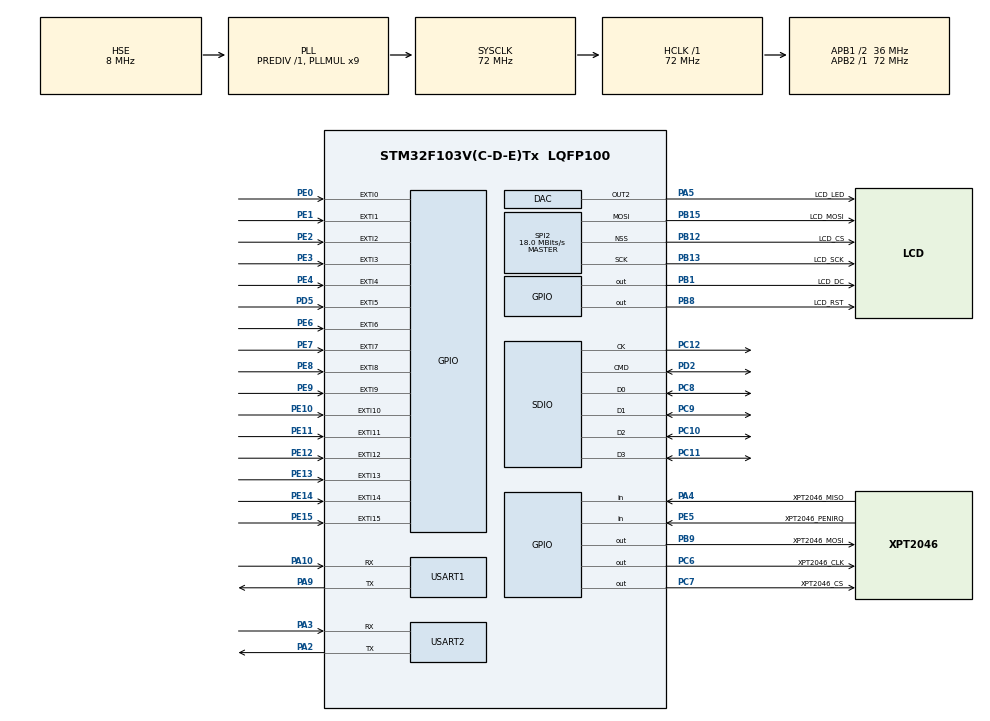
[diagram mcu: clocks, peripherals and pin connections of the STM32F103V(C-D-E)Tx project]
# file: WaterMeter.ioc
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DAC.DAC_Trigger2=DAC_TRIGGER_NONE
Dma.Request0=SPI2_TX
Dma.SPI2_TX.0.Direction=DMA_MEMORY_TO_PERIPH
Dma.SPI2_TX.0.Instance=DMA1_Channel5
Dma.SPI2_TX.0.MemDataAlignment=DMA_MDATAALIGN_BYTE
Dma.SPI2_TX.0.MemInc=DMA_MINC_ENABLE
Dma.SPI2_TX.0.Mode=DMA_NORMAL
Dma.SPI2_TX.0.PeriphDataAlignment=DMA_PDATAALIGN_BYTE
Dma.SPI2_TX.0.PeriphInc=DMA_PINC_DISABLE
Dma.SPI2_TX.0.Priority=DMA_PRIORITY_VERY_HIGH
FATFS._CODE_PAGE=437
FATFS._USE_LFN=2
FREERTOS.Tasks01=defaultTask,24,128,StartDefaultTask,Default,NULL,Dynamic,NULL,NULL;Task_Exti,8,150,TaskFunc_Exti,As external,NULL,Static,Task_ExtiBuffer,Task_ExtiControlBlock;Task_Screen,40,550,TaskFunc_Screen,As external,NULL,Static,Task_ScreenBuffer,Task_ScreenControlBlock;Task_Air724Rx,8,128,TaskFunc_Air724Rx,As external,NULL,Static,Task_Air724RxBuffer,Task_Air724RxControlBlock;Task_Air724Tx,8,128,TaskFunc_Air724Tx,As external,NULL,Static,Task_Air724TxBuffer,Task_Air724TxControlBlock
FREERTOS.configMAX_TASK_NAME_LEN=32
FREERTOS.configRECORD_STACK_HIGH_ADDRESS=1
FREERTOS.configTOTAL_HEAP_SIZE=2048
FREERTOS.configUSE_NEWLIB_REENTRANT=1
Mcu.Family=STM32F1
Mcu.Name=STM32F103V(C-D-E)Tx
Mcu.Package=LQFP100
NVIC.DMA1_Channel5_IRQn=true\:0\:0\:true\:false\:true\:false\:false\:true\:true
NVIC.EXTI0_IRQn=true\:1\:0\:true\:false\:true\:false\:true\:true\:true
NVIC.EXTI15_10_IRQn=true\:1\:0\:true\:false\:true\:false\:true\:true\:true
NVIC.EXTI1_IRQn=true\:1\:0\:true\:false\:true\:false\:true\:true\:true
NVIC.EXTI2_IRQn=true\:1\:0\:true\:false\:true\:false\:true\:true\:true
NVIC.EXTI3_IRQn=true\:1\:0\:true\:false\:true\:false\:true\:true\:true
NVIC.EXTI4_IRQn=true\:1\:0\:true\:false\:true\:false\:true\:true\:true
NVIC.EXTI9_5_IRQn=true\:1\:0\:true\:false\:true\:false\:true\:true\:true
NVIC.PriorityGroup=NVIC_PRIORITYGROUP_4
NVIC.TIM7_IRQn=true\:15\:0\:false\:false\:true\:false\:false\:true\:true
NVIC.TimeBase=TIM7_IRQn
NVIC.TimeBaseIP=TIM7
OSC_IN.Mode=HSE-External-Oscillator
OSC_IN.Signal=RCC_OSC_IN
OSC_OUT.Mode=HSE-External-Oscillator
OSC_OUT.Signal=RCC_OSC_OUT
PA10.Mode=Asynchronous
PA10.Signal=USART1_RX
PA13.Mode=Serial_Wire
PA13.Signal=SYS_JTMS-SWDIO
PA14.Mode=Serial_Wire
PA14.Signal=SYS_JTCK-SWCLK
PA2.Mode=Asynchronous
PA2.Signal=USART2_TX
PA3.Mode=Asynchronous
PA3.Signal=USART2_RX
PA4.GPIO_Label=XPT2046_MISO
PA4.Signal=GPIO_Input
PA5.GPIO_Label=LCD_LED
PA5.Signal=COMP_DAC2_group
PA9.Mode=Asynchronous
PA9.Signal=USART1_TX
PB1.GPIO_Label=LCD_DC
PB1.GPIO_Speed=GPIO_SPEED_FREQ_HIGH
PB1.PinState=GPIO_PIN_RESET
PB1.Signal=GPIO_Output
PB12.GPIO_Label=LCD_CS
PB12.Mode=NSS_Signal_Hard_Output
PB12.Signal=SPI2_NSS
PB13.GPIO_Label=LCD_SCK
PB13.Mode=TX_Only_Simplex_Unidirect_Master
PB13.Signal=SPI2_SCK
PB15.GPIO_Label=LCD_MOSI
PB15.Mode=TX_Only_Simplex_Unidirect_Master
PB15.Signal=SPI2_MOSI
PB8.GPIO_Label=LCD_RST
PB8.GPIO_Speed=GPIO_SPEED_FREQ_HIGH
PB8.Signal=GPIO_Output
PB9.GPIO_Label=XPT2046_MOSI
PB9.GPIO_Speed=GPIO_SPEED_FREQ_HIGH
PB9.Signal=GPIO_Output
PC10.Mode=SD_4_bits_Wide_bus
PC10.Signal=SDIO_D2
PC11.Mode=SD_4_bits_Wide_bus
PC11.Signal=SDIO_D3
PC12.Mode=SD_4_bits_Wide_bus
PC12.Signal=SDIO_CK
PC6.GPIO_Label=XPT2046_CLK
PC6.GPIO_Speed=GPIO_SPEED_FREQ_HIGH
PC6.Signal=GPIO_Output
PC7.GPIO_Label=XPT2046_CS
PC7.GPIO_Speed=GPIO_SPEED_FREQ_HIGH
PC7.Signal=GPIO_Output
PC8.Mode=SD_4_bits_Wide_bus
PC8.Signal=SDIO_D0
PC9.Mode=SD_4_bits_Wide_bus
PC9.Signal=SDIO_D1
PD2.Mode=SD_4_bits_Wide_bus
PD2.Signal=SDIO_CMD
PD5.Signal=GPXTI5
PE0.Signal=GPXTI0
PE1.Signal=GPXTI1
PE10.Signal=GPXTI10
PE11.Signal=GPXTI11
PE12.Signal=GPXTI12
PE13.Signal=GPXTI13
PE14.Signal=GPXTI14
PE15.Signal=GPXTI15
PE2.Signal=GPXTI2
PE3.Signal=GPXTI3
PE4.Signal=GPXTI4
PE5.GPIO_Label=XPT2046_PENIRQ
PE5.Signal=GPIO_Input
PE6.Signal=GPXTI6
PE7.Signal=GPXTI7
PE8.Signal=GPXTI8
PE9.Signal=GPXTI9
ProjectManager.HeapSize=0x100
ProjectManager.StackSize=0x200
ProjectManager.TargetToolchain=STM32CubeIDE
RCC.AHBFreq_Value=72000000
RCC.APB1CLKDivider=RCC_HCLK_DIV2
RCC.APB1Freq_Value=36000000
RCC.APB1TimFreq_Value=72000000
RCC.APB2Freq_Value=72000000
RCC.APB2TimFreq_Value=72000000
RCC.HCLKFreq_Value=72000000
RCC.PLLMUL=RCC_PLL_MUL9
RCC.PLLSourceVirtual=RCC_PLLSOURCE_HSE
RCC.SYSCLKFreq_VALUE=72000000
RCC.SYSCLKSource=RCC_SYSCLKSOURCE_PLLCLK
RCC.USBFreq_Value=72000000
SH.COMP_DAC2_group.0=DAC_OUT2,DAC_OUT2
SPI2.BaudRatePrescaler=SPI_BAUDRATEPRESCALER_2
SPI2.CalculateBaudRate=18.0 MBits/s
SPI2.Direction=SPI_DIRECTION_2LINES
SPI2.Mode=SPI_MODE_MASTER
SPI2.VirtualNSS=VM_NSSHARD
SPI2.VirtualType=VM_MASTER
USART1.VirtualMode=VM_ASYNC
USART2.VirtualMode=VM_ASYNC
VP_FATFS_VS_SDIO.Mode=SDIO
VP_FREERTOS_VS_CMSIS_V2.Mode=CMSIS_V2
VP_SYS_VS_tim7.Mode=TIM7
board=custom

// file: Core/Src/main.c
/* USER CODE BEGIN Header */
/**
 ******************************************************************************
 * @file           : main.c
 * @brief          : Main program body
 ******************************************************************************
 * @attention
 *
 * Copyright (c) 2022 STMicroelectronics.
 * All rights reserved.
 *
 * This software is licensed under terms that can be found in the LICENSE file
 * in the root directory of this software component.
 * If no LICENSE file comes with this software, it is provided AS-IS.
 *
 ******************************************************************************
 */
/* USER CODE END Header */
#include "main.h"
#include "cmsis_os.h"
#include "dac.h"
#include "dma.h"
#include "fatfs.h"
#include "sdio.h"
#include "spi.h"
#include "usart.h"
#include "gpio.h"

/* USER CODE BEGIN Includes */
#include "stdio.h"
/* USER CODE END Includes */

void SystemClock_Config(void);
void MX_FREERTOS_Init(void);

int main(void) {

    /* MCU Configuration--------------------------------------------------------*/

    /* Reset of all peripherals, Initializes the Flash interface and the Systick. */
    HAL_Init();

    /* Configure the system clock */
    SystemClock_Config();

    /* Initialize all configured peripherals */
    MX_GPIO_Init();
    MX_DMA_Init();
    MX_SPI2_Init();
    MX_USART1_UART_Init();
    MX_SDIO_SD_Init();
    MX_FATFS_Init();
    MX_USART2_UART_Init();
    MX_DAC_Init();
    /* USER CODE BEGIN 2 */
    HAL_DAC_SetValue(&hdac, DAC_CHANNEL_2, DAC_ALIGN_12B_R, 4095);
    HAL_DAC_Start(&hdac, DAC_CHANNEL_2);

    /* USER CODE END 2 */

    /* Init scheduler */
    osKernelInitialize(); /* Call init function for freertos objects (in freertos.c) */
    MX_FREERTOS_Init();

    /* Start scheduler */
    osKernelStart();

    /* We should never get here as control is now taken by the scheduler */
    /* Infinite loop */
    while (1) {

    }
}

void SystemClock_Config(void) {
    RCC_OscInitTypeDef RCC_OscInitStruct = {0};
    RCC_ClkInitTypeDef RCC_ClkInitStruct = {0};

    /** Initializes the RCC Oscillators according to the specified parameters
     * in the RCC_OscInitTypeDef structure.
     */
    RCC_OscInitStruct.OscillatorType = RCC_OSCILLATORTYPE_HSE;
    RCC_OscInitStruct.HSEState = RCC_HSE_ON;
    RCC_OscInitStruct.HSEPredivValue = RCC_HSE_PREDIV_DIV1;
    RCC_OscInitStruct.HSIState = RCC_HSI_ON;
    RCC_OscInitStruct.PLL.PLLState = RCC_PLL_ON;
    RCC_OscInitStruct.PLL.PLLSource = RCC_PLLSOURCE_HSE;
    RCC_OscInitStruct.PLL.PLLMUL = RCC_PLL_MUL9;
    if (HAL_RCC_OscConfig(&RCC_OscInitStruct) != HAL_OK) {
        Error_Handler();
    }

    /** Initializes the CPU, AHB and APB buses clocks
     */
    RCC_ClkInitStruct.ClockType =
        RCC_CLOCKTYPE_HCLK | RCC_CLOCKTYPE_SYSCLK | RCC_CLOCKTYPE_PCLK1 | RCC_CLOCKTYPE_PCLK2;
    RCC_ClkInitStruct.SYSCLKSource = RCC_SYSCLKSOURCE_PLLCLK;
    RCC_ClkInitStruct.AHBCLKDivider = RCC_SYSCLK_DIV1;
    RCC_ClkInitStruct.APB1CLKDivider = RCC_HCLK_DIV2;
    RCC_ClkInitStruct.APB2CLKDivider = RCC_HCLK_DIV1;

    if (HAL_RCC_ClockConfig(&RCC_ClkInitStruct, FLASH_LATENCY_2) != HAL_OK) {
        Error_Handler();
    }
}

void HAL_TIM_PeriodElapsedCallback(TIM_HandleTypeDef *htim) {
    if (htim->Instance == TIM7) {
        HAL_IncTick();
    }
}

void Error_Handler(void) {
    __disable_irq();
    while (1) {
    }
}

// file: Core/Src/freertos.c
/* USER CODE BEGIN Header */
/**
 ******************************************************************************
 * File Name          : freertos.c
 * Description        : Code for freertos applications
 ******************************************************************************
 * @attention
 *
 * Copyright (c) 2022 STMicroelectronics.
 * All rights reserved.
 *
 * This software is licensed under terms that can be found in the LICENSE file
 * in the root directory of this software component.
 * If no LICENSE file comes with this software, it is provided AS-IS.
 *
 ******************************************************************************
 */
/* USER CODE END Header */

#include "FreeRTOS.h"
#include "task.h"
#include "main.h"
#include "cmsis_os.h"

/* USER CODE BEGIN Includes */
#include "stdio.h"
/* USER CODE END Includes */

typedef StaticTask_t osStaticThreadDef_t;

/* Definitions for defaultTask */
osThreadId_t defaultTaskHandle;
const osThreadAttr_t defaultTask_attributes = {
  .name = "defaultTask",
  .stack_size = 128 * 4,
  .priority = (osPriority_t) osPriorityNormal,
};
/* Definitions for Task_Exti */
osThreadId_t Task_ExtiHandle;
uint32_t Task_ExtiBuffer[ 150 ];
osStaticThreadDef_t Task_ExtiControlBlock;
const osThreadAttr_t Task_Exti_attributes = {
  .name = "Task_Exti",
  .cb_mem = &Task_ExtiControlBlock,
  .cb_size = sizeof(Task_ExtiControlBlock),
  .stack_mem = &Task_ExtiBuffer[0],
  .stack_size = sizeof(Task_ExtiBuffer),
  .priority = (osPriority_t) osPriorityLow,
};
/* Definitions for Task_Screen */
osThreadId_t Task_ScreenHandle;
uint32_t Task_ScreenBuffer[ 550 ];
osStaticThreadDef_t Task_ScreenControlBlock;
const osThreadAttr_t Task_Screen_attributes = {
  .name = "Task_Screen",
  .cb_mem = &Task_ScreenControlBlock,
  .cb_size = sizeof(Task_ScreenControlBlock),
  .stack_mem = &Task_ScreenBuffer[0],
  .stack_size = sizeof(Task_ScreenBuffer),
  .priority = (osPriority_t) osPriorityHigh,
};
/* Definitions for Task_Air724Rx */
osThreadId_t Task_Air724RxHandle;
uint32_t Task_Air724RxBuffer[ 128 ];
osStaticThreadDef_t Task_Air724RxControlBlock;
const osThreadAttr_t Task_Air724Rx_attributes = {
  .name = "Task_Air724Rx",
  .cb_mem = &Task_Air724RxControlBlock,
  .cb_size = sizeof(Task_Air724RxControlBlock),
  .stack_mem = &Task_Air724RxBuffer[0],
  .stack_size = sizeof(Task_Air724RxBuffer),
  .priority = (osPriority_t) osPriorityLow,
};
/* Definitions for Task_Air724Tx */
osThreadId_t Task_Air724TxHandle;
uint32_t Task_Air724TxBuffer[ 128 ];
osStaticThreadDef_t Task_Air724TxControlBlock;
const osThreadAttr_t Task_Air724Tx_attributes = {
  .name = "Task_Air724Tx",
  .cb_mem = &Task_Air724TxControlBlock,
  .cb_size = sizeof(Task_Air724TxControlBlock),
  .stack_mem = &Task_Air724TxBuffer[0],
  .stack_size = sizeof(Task_Air724TxBuffer),
  .priority = (osPriority_t) osPriorityLow,
};

void StartDefaultTask(void *argument);
extern void TaskFunc_Exti(void *argument);
extern void TaskFunc_Screen(void *argument);
extern void TaskFunc_Air724Rx(void *argument);
extern void TaskFunc_Air724Tx(void *argument);

void MX_FREERTOS_Init(void); /* (MISRA C 2004 rule 8.1) */

void MX_FREERTOS_Init(void) {

  /* Create the thread(s) */
  /* creation of defaultTask */
  defaultTaskHandle = osThreadNew(StartDefaultTask, NULL, &defaultTask_attributes);

  /* creation of Task_Exti */
  Task_ExtiHandle = osThreadNew(TaskFunc_Exti, NULL, &Task_Exti_attributes);

  /* creation of Task_Screen */
  Task_ScreenHandle = osThreadNew(TaskFunc_Screen, NULL, &Task_Screen_attributes);

  /* creation of Task_Air724Rx */
  Task_Air724RxHandle = osThreadNew(TaskFunc_Air724Rx, NULL, &Task_Air724Rx_attributes);

  /* creation of Task_Air724Tx */
  Task_Air724TxHandle = osThreadNew(TaskFunc_Air724Tx, NULL, &Task_Air724Tx_attributes);

}

void StartDefaultTask(void *argument)
{
  /* USER CODE BEGIN StartDefaultTask */
    /* Infinite loop */
//    vTaskDelete(NULL);
    /* Infinite loop */

    while (1) {
        vTaskDelay(2000);
        printf("\n\n%lu\tdefaultTask\n", uxTaskGetStackHighWaterMark(defaultTaskHandle));
        printf("%lu\tTask_ExtiHandle\n", uxTaskGetStackHighWaterMark(Task_ExtiHandle));
        printf("%lu\tTask_ScreenHandle\n", uxTaskGetStackHighWaterMark(Task_ScreenHandle));
        printf("%lu\tTask_Air724RxHandle\n", uxTaskGetStackHighWaterMark(Task_Air724RxHandle));
        printf("%lu\tTask_Air724TxHandle\n", uxTaskGetStackHighWaterMark(Task_Air724TxHandle));
    }
  /* USER CODE END StartDefaultTask */
}
